# nrf9220_sysctrl register map
Vendor: Nordic Semiconductor; Series: nRF92; File version: 1
Registers are 32-bit, read-write, reset 0x0 unless marked. A register's access mark holds for its fields unless they carry their own. Offsets are from the block's base; [hi:lo] are bit positions; lines under a group give offsets from that group; {n}, {i} and the like mark numbered series.

## VPRCLIC — VPR CLIC registers
Base 0xF0000000
0x00 CLIC group — Unspecified
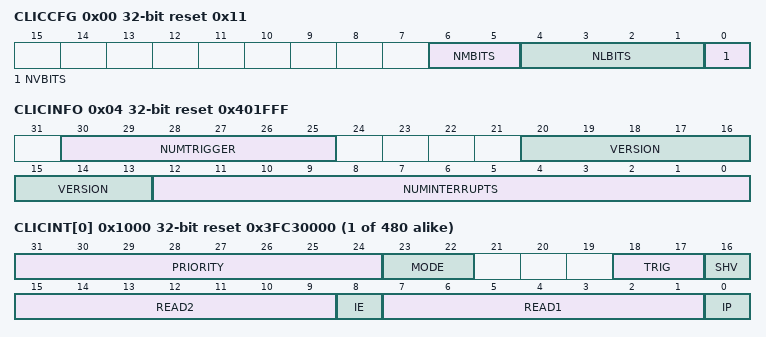
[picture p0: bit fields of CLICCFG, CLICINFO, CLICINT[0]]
  0x00 CLICCFG ro reset 0x11 — CLIC configuration.
    [6:5] NMBITS — Interrupt privilege mode.
      0=ModeM (All interrupts are M-mode only)
    [4:1] NLBITS — Interrupt level encoding.
      8=Eight (8 bits = interrupt levels encoded in eight bits)
    [0] NVBITS — Selective interrupt hardware vectoring.
      1=Implemented (Selective interrupt hardware vectoring is implemented)
  0x04 CLICINFO ro reset 0x401FFF — CLIC information.
    [30:25] NUMTRIGGER — Number of maximum interrupt triggers supported
    [20:13] VERSION
    [12:0] NUMINTERRUPTS — Maximum number of interrupts supported.
  {0x1000+4j} CLICINT[{j}] (j=0..479) reset 0x3FC30000 — Description collection: Interrupt control register for IRQ number [n].
    [31:24] PRIORITY — Interrupt priority level
      63=PRIOLEVEL0 (Priority level 0); 127=PRIOLEVEL1 (Priority level 1); 191=PRIOLEVEL2 (Priority level 2); 255=PRIOLEVEL3 (Priority level 3)
    [23:22] MODE ro — Privilege mode.
      3=MachineMode
    [18:17] TRIG ro — Trigger type and polarity for each interrupt input.
      1=EdgeTriggered (Interrupts are edge-triggered)
    [16] SHV ro — Selective Hardware Vectoring.
      1=Vectored (Hardware vectored)
    [15:9] READ2 ro — Read as 0, write ignored.
    [8] IE — Interrupt enable bit.
      0=Disabled (Interrupt disabled); 1=Enabled (Interrupt enabled)
    [7:1] READ1 ro — Read as 0, write ignored.
    [0] IP — Interrupt Pending bit.
      0=NotPending (Interrupt not pending); 1=Pending (Interrupt pending)

## RAMC110 — RAM Controller 0
Base 0x5F083000
Same registers: RAMC111 0x5F084000, RAMC120 0x5F8C3000, RAMC121 0x5F8C4000, RAMC130 0x5F903000, RAMC131 0x5F904000
0x500 WAITSTATES — Waitstates for read operations.
  [0] WAITSTATES — Number of waitstates for a read from the RAM.

## SHA3 — CRACEN
Base 0x5F088000
0x100 EVENTS_CRYPTOMASTER — Event indicating that interrupt triggered at Cryptomaster
  [0] EVENTS_CRYPTOMASTER
    0=NotGenerated (Event not generated); 1=Generated (Event generated)
0x300 INTEN — Enable or disable interrupt
  [0] CRYPTOMASTER — Enable or disable interrupt for event CRYPTOMASTER
    0=Disabled; 1=Enabled
0x304 INTENSET — Enable interrupt
  [0] CRYPTOMASTER — Write '1' to enable interrupt for event CRYPTOMASTER
    on read: 0=Disabled (Read: Disabled); 1=Enabled (Read: Enabled) | on write: 1=Set (Enable)
0x308 INTENCLR — Disable interrupt
  [0] CRYPTOMASTER — Write '1' to disable interrupt for event CRYPTOMASTER
    on read: 0=Disabled (Read: Disabled); 1=Enabled (Read: Enabled) | on write: 1=Clear (Disable)
0x30C INTPEND ro — Pending interrupts
  [0] CRYPTOMASTER — Read pending status of interrupt for event CRYPTOMASTER
    on read: 0=NotPending (Read: Not pending); 1=Pending (Read: Pending)
0x400 ENABLE — Enable CRACEN peripheral modules.
  [0] CRYPTOMASTER — Enable cryptomaster
    0=Disabled (Cryptomaster disabled.); 1=Enabled (Cryptomaster enabled.)

## PPIB110 — PPIB APB registers 0
Base 0x5F098000
Same registers: PPIB120 0x5F8EE000, PPIB121 0x5F8EF000, PPIB130 0x5F925000, PPIB131 0x5F926000, PPIB132 0x5F98D000, PPIB133 0x5F99D000, PPIB134 0x5F9AD000, PPIB135 0x5F9BD000
{0x0+4i} TASKS_SEND[{i}] (i=0..31) wo — Description collection: This task is unused, but the PPIB provides the SUBSCRIBE task to connect SEND [n] task.
  [0] TASKS_SEND — This task is unused, but the PPIB provides the SUBSCRIBE task to connect SEND [n] task.
    1=Trigger task
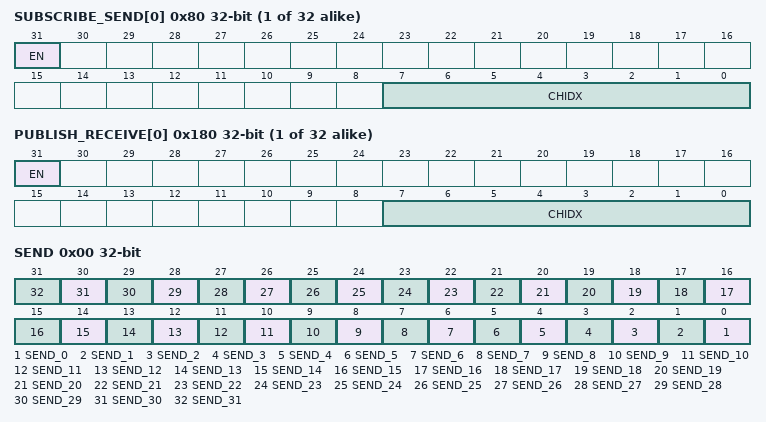
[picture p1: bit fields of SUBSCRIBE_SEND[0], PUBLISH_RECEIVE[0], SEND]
{0x80+4i} SUBSCRIBE_SEND[{i}] (i=0..31) — Description collection: Subscribe configuration for task SEND[n]
  [31] EN
    0=Disabled (Disable subscription); 1=Enabled (Enable subscription)
  [7:0] CHIDX — DPPI channel that task SEND[n] will subscribe to
{0x100+4i} EVENTS_RECEIVE[{i}] (i=0..31) — Description collection: This event is unused, but the PPIB provides the PUBLISH event to connect RECEIVE [n] event.
  [0] EVENTS_RECEIVE — This event is unused, but the PPIB provides the PUBLISH event to connect RECEIVE [n] event.
    0=NotGenerated (Event not generated); 1=Generated (Event generated)
{0x180+4i} PUBLISH_RECEIVE[{i}] (i=0..31) — Description collection: Publish configuration for event RECEIVE[n]
  [31] EN
    0=Disabled (Disable publishing); 1=Enabled (Enable publishing)
  [7:0] CHIDX — DPPI channel that event RECEIVE[n] will publish to
0x400 OVERFLOW group — Unspecified
  0x00 SEND — The task overflow for SEND tasks using SUBSCRIBE_SEND. Write 0 to clear.
    [all] fields
      1=Overflow (Task overflow is happened.); 0=NoOverflow (Task overflow is not happened.)
    [n] SEND_{n} (n=0..31) — The status for tasks overflow at SUBSCRIBE_SEND[{n}].
